# Musca_B1 register map
Vendor: ARM Ltd.; Series: ARMv8-M Mainline; File version: 1.0
CPU: CM33 r0p2, little endian, MPU, FPU, 4 interrupt priority bits, 8 SAU regions
Registers are 32-bit, read-write, reset 0x0 unless marked. A register's access mark holds for its fields unless they carry their own. Offsets are from the block's base; [hi:lo] are bit positions; {n}, {i} and the like mark numbered series; 'fields as' and 'values as' point back to an identical list.

## SystemControl
Base 0x50021000
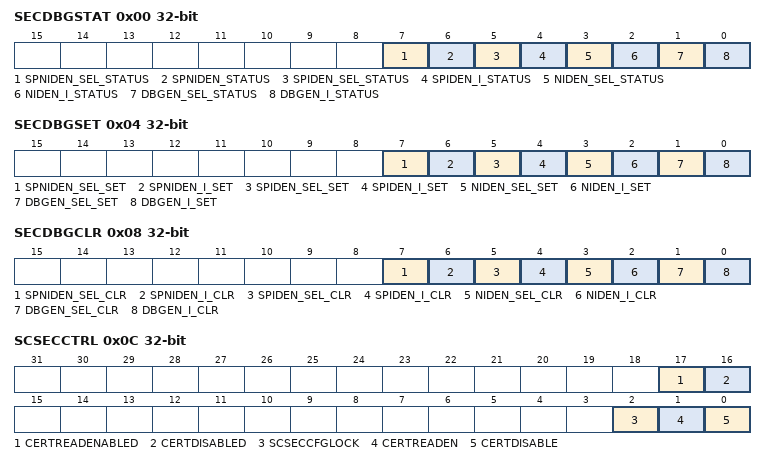
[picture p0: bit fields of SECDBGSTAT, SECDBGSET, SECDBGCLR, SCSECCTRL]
0x00 SECDBGSTAT ro — Secure Debug Configuration Status
  [7] SPNIDEN_SEL_STATUS — Secure privilege non-invasive debug enable selector value
    1=enable (Secure privilege non-invasive debug enable selector); 0=disable (Secure privilege non-invasive debug disable selector)
  [6] SPNIDEN_STATUS — Secure privilege non-invasive debug enable value
    1=enable (Secure privilege non-invasive debug enable); 0=disable (Secure privilege non-invasive debug disable)
  [5] SPIDEN_SEL_STATUS — Secure privilege invasive debug enable selector value
    1=enable (Secure privilege invasive debug enable selector); 0=disable (Secure privilege invasive debug disable selector)
  [4] SPIDEN_I_STATUS — Secure privilege invasive debug enable value
    1=enable (Secure privilege invasive debug enable); 0=disable (Secure privilege invasive debug disable)
  [3] NIDEN_SEL_STATUS — Non-invasive debug enable selector value
    1=enable (non-invasive debug enable selector); 0=disable (non-invasive debug disable selector)
  [2] NIDEN_I_STATUS — Non-invasive debug enable value
    1=enable (non-invasive debug enable); 0=disable (non-invasive debug disable)
  [1] DBGEN_SEL_STATUS — Debug enable selector value
    1=enable (debug enable selector); 0=disable (debug disable selector)
  [0] DBGEN_I_STATUS — Debug enable value
    1=enable (debug enable); 0=disable (debug disable)
0x04 SECDBGSET wo — Secure Debug Configuration Set
  [7] SPNIDEN_SEL_SET — Secure privilege non-invasive debug enable selector set control
    1=enable (Secure privilege non-invasive debug enable selector set control); 0=disable (Secure privilege non-invasive debug disable selector set control)
  [6] SPNIDEN_I_SET — Secure privilege non-invasive debug enable set control
    1=enable (Secure privilege non-invasive debug enable set control); 0=disable (Secure privilege non-invasive debug disable set control)
  [5] SPIDEN_SEL_SET — Secure privilege invasive debug enable selector set control
    1=enable (Secure privilege invasive debug enable selector set control); 0=disable (Secure privilege invasive debug disable selector set control)
  [4] SPIDEN_I_SET — Secure privilege invasive debug enable set control
    1=enable (Secure privilege invasive debug enable set control); 0=disable (Secure privilege invasive debug disable set control)
  [3] NIDEN_SEL_SET — Non-invasive debug enable selector set control
    1=enable (non-invasive debug enable selector set control); 0=disable (non-invasive debug disable selector set control)
  [2] NIDEN_I_SET — Non-invasive debug enable set control
    1=enable (non-invasive debug enable set control); 0=disable (non-invasive debug disable set control)
  [1] DBGEN_SEL_SET — Debug enable selector set control
    1=enable (debug enable selector set control); 0=disable (debug disable selector set control)
  [0] DBGEN_I_SET — High active debug enable set control
0x08 SECDBGCLR wo — Secure Debug Configuration Clear
  [7] SPNIDEN_SEL_CLR — Secure privilege non-invasive debug enable selector clear control
    1=enable (Secure privilege non-invasive debug enable selector clear control); 0=disable (Secure privilege non-invasive debug disable selector clear control)
  [6] SPNIDEN_I_CLR — Secure privilege non-invasive debug enable clear control
    1=enable (Secure privilege non-invasive debug enable clear control); 0=disable (Secure privilege non-invasive debug disable clear control)
  [5] SPIDEN_SEL_CLR — Secure privilege invasive debug enable selector clear control
    1=enable (Secure privilege invasive debug enable selector clear control); 0=disable (Secure privilege invasive debug disable selector clear control)
  [4] SPIDEN_I_CLR — Secure privilege invasive debug enable clear control
    1=enable (Secure privilege invasive debug enable clear control); 0=disable (Secure privilege invasive debug disable clear control)
  [3] NIDEN_SEL_CLR — Non-invasive debug enable selector clear control
    1=enable (non-invasive debug enable selector clear control); 0=disable (non-invasive debug disable selector clear control)
  [2] NIDEN_I_CLR — Non-invasive debug enable clear control
    1=enable (non-invasive debug enable clear control); 0=disable (non-invasive debug disable clear control)
  [1] DBGEN_SEL_CLR — Debug enable selector clear control
    1=enable (debug enable selector clear control); 0=disable (debug disable selector clear control)
  [0] DBGEN_I_CLR — Debug enable clear control
    1=enable (debug enable clear control); 0=disable (debug disable clear control)
0x0C SCSECCTRL — System Security Control
  [17] CERTREADENABLED — Indicates whether the certification read access is enabled
    1=enabled (certification read access is enabled); 0=disabled (certification read access is disabled)
  [16] CERTDISABLED — Indicates that the Certification write path has been disabled
    1=disabled (Certification write path has been disabled); 0=enabled (Certification write path has been enabled)
  [2] SCSECCFGLOCK — Control to disable writes to security-related control registers in this register block
    1=disable (control to disable writes to security-related control registers in this register block); 0=enable (control to enable writes to security-related control registers in this register block)
  [1] CERTREADEN — Control to enable read access on the certification path as long as CERTDISABLE is also LOW
    1=enable (control to enable read access on the certification path as long as CERTDISABLE is also LOW); 0=disable (control to disable read access on the certification path as long as CERTDISABLE is also LOW)
  [0] CERTDISABLE — Control to disable certification path
    1=disable (control to disable certification path); 0=enable (control to enable certification path)
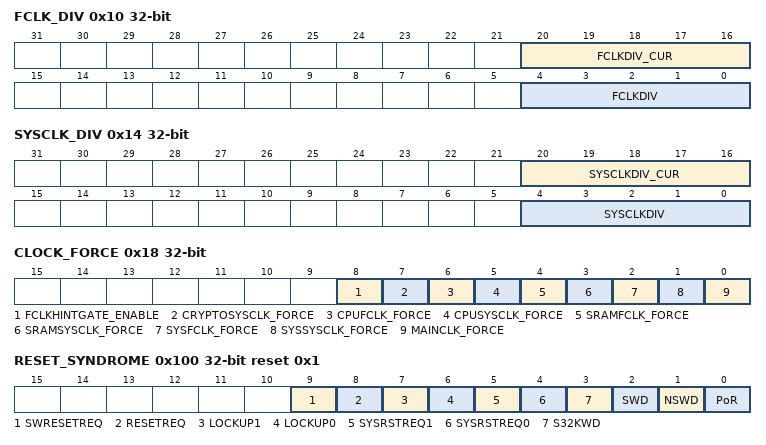
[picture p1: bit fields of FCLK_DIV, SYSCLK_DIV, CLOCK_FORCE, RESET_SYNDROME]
0x10 FCLK_DIV — Fast Clock Divider Configuration
  [20:16] FCLKDIV_CUR ro — Clock Divider Current Value.
  [4:0] FCLKDIV — FCLK from MAINCLK Clock Divider Ratio Request
0x14 SYSCLK_DIV — System Clock Divider Configuration
  [20:16] SYSCLKDIV_CUR ro — Clock Divider Current Value
  [4:0] SYSCLKDIV — SYSCLK from FCLK Clock Divider Ratio Request
0x18 CLOCK_FORCE
  [8] FCLKHINTGATE_ENABLE — Enable FCLK gating by HINTSYSCLKEN when CPU 1 is OFF
    1=Enable FCLK gating by HINTSYSCLKEN when CPU 1 is OFF; 0=latency (improve SRAM3 access latency at the cost of increased power consumption)
  [7] CRYPTOSYSCLK_FORCE — Force all CryptoCell clocks to run when set to HIGH
  [6] CPUFCLK_FORCE — Force all CPU FCLK to run when set to HIGH
  [5] CPUSYSCLK_FORCE — Force all CPU SYSCLK to run when set to HIGH
  [4] SRAMFCLK_FORCE — Force SRAM Local FCLK to run when set to HIGH
  [3] SRAMSYSCLK_FORCE — Force SRAM Local SYSCLK to run when set to HIGH
  [2] SYSFCLK_FORCE — Force Base element Local FCLK to run when set to HIGH
  [1] SYSSYSCLK_FORCE — Force Base element Local SYSCLK to run when set to HIGH
  [0] MAINCLK_FORCE — Force MAINCLK to run when set to HIGH
0x100 RESET_SYNDROME reset 0x1
  [9] SWRESETREQ wo — Software Reset Request
  [8] RESETREQ wo — External Reset Request
  [7] LOCKUP1 wo — CPU 1 Lock-up Status
  [6] LOCKUP0 wo — CPU 0 Lock-up Status
  [5] SYSRSTREQ1 wo — CPU 1 System Reset Request
  [4] SYSRSTREQ0 wo — CPU 0 System Reset Request
  [3] S32KWD wo — Watchdog on the S32KCLK clock
  [2] SWD wo — Secure watchdog
  [1] NSWD wo — Non-secure watchdog
  [0] PoR wo — Power-on
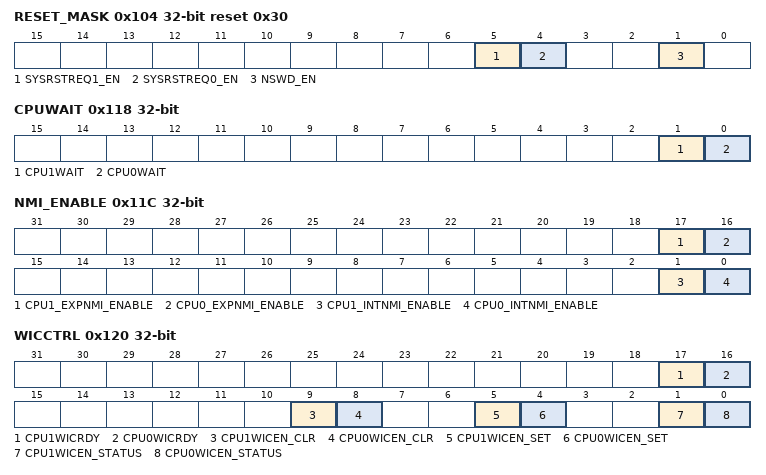
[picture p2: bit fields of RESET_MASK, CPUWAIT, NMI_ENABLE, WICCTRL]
0x104 RESET_MASK reset 0x30
  [5] SYSRSTREQ1_EN — Enable Merging CPU 0 System Reset Request
    1=enabled (Enable Merging CPU 1 System Reset Request); 0=Disabled Merging CPU 1 System Reset Request
  [4] SYSRSTREQ0_EN — Enable Merging CPU 0 System Reset Request
    1=enabled (Enable Merging CPU 0 System Reset Request); 0=Disabled Merging CPU 0 System Reset Request
  [1] NSWD_EN — Enable NON-SECURE WATCHDOG Reset
    1=enabled (Enable NON-SECURE WATCHDOG Reset); 0=Disabled NON-SECURE WATCHDOG Reset
0x108 SWRESET wo — Software Reset
  [9] SWRESETREQ — High Active Software Reset Request
0x10C GRETREG — General Purpose Retention
  [15:0] GRETREG — General Purpose Retention Register
0x110 INITSVRTOR0 — Initial Secure Reset Vector Register For CPU 0
  [31:7] INITSVTOR0 — Default Secure Vector table offset at reset for CPU 0
0x114 INITSVRTOR1 — Initial Secure Reset Vector Register For CPU 1
  [31:7] INITSVTOR1 — Default Secure Vector table offset at reset for CPU 1
0x118 CPUWAIT — CPU Boot wait control after reset
  [1] CPU1WAIT — CPU 1 waits at boot and whether CPU0 powers up
    0=normally or power-up (CPU1 boot normally. From Power ON reset, nSRST reset or Watchdog Reset, CPU 0 powers up); 1=wait or no power-up (CPU1 wait. From Power ON reset, nSRST reset or Watchdog Reset, CPU 0 do not power up)
  [0] CPU0WAIT — CPU 0 waits at boot and whether CPU1 powers up
    0=normally or power-up (CPU0 boot normally. From Power ON reset, nSRST reset or Watchdog Reset, CPU 1 powers up); 1=wait or no power-up (CPU0 wait. From Power ON reset, nSRST reset or Watchdog Reset, CPU 1 do not power up)
0x11C NMI_ENABLE
  [17] CPU1_EXPNMI_ENABLE — CPU1 Externally Sourced NMI Enable
    1=enable (CPU1 Externally Sourced NMI Enabled); 0=disabled (CPU1 Externally Sourced NMI Disabled)
  [16] CPU0_EXPNMI_ENABLE — CPU0 Externally Sourced NMI Enable
    1=enable (CPU0 Externally Sourced NMI Enabled); 0=disabled (CPU0 Externally Sourced NMI Disabled)
  [1] CPU1_INTNMI_ENABLE — CPU1 Internally Sourced NMI Enable
    1=enable (CPU1 Internally Sourced NMI Enabled); 0=disabled (CPU1 Internally Sourced NMI Disabled)
  [0] CPU0_INTNMI_ENABLE — CPU0 Internally Sourced NMI Enable
    1=enable (CPU0 Internally Sourced NMI Enabled); 0=disabled (CPU0 Internally Sourced NMI Disabled)
0x120 WICCTRL — WIC request and acknowledge handshake
  [17] CPU1WICRDY ro — CPU 1 WIC Enable Acknowledge
    1=enabled (CPU 1 WIC Enabled); 0=disabled (CPU 1 WIC Disabled)
  [16] CPU0WICRDY ro — CPU 0 WIC Enable Acknowledge
    1=enabled (CPU 0 WIC Enabled); 0=disabled (CPU 0 WIC Disabled)
  [9] CPU1WICEN_CLR wo — High Active CPU 1 WIC Enable Request Clear
  [8] CPU0WICEN_CLR wo — High Active CPU 0 WIC Enable Request Clear
  [5] CPU1WICEN_SET wo — High Active CPU 1 WIC Enable Request Set
  [4] CPU0WICEN_SET wo — High Active CPU 0 WIC Enable Request Set
  [1] CPU1WICEN_STATUS ro — CPU 1 WIC Enable Request Status
    1=enable (CPU 1 WIC request enabled); 0=disabled (CPU 1 WIC request disabled)
  [0] CPU0WICEN_STATUS ro — CPU 0 WIC Enable Request Status
    1=enable (CPU 0 WIC request enabled); 0=disabled (CPU 0 WIC request disabled)
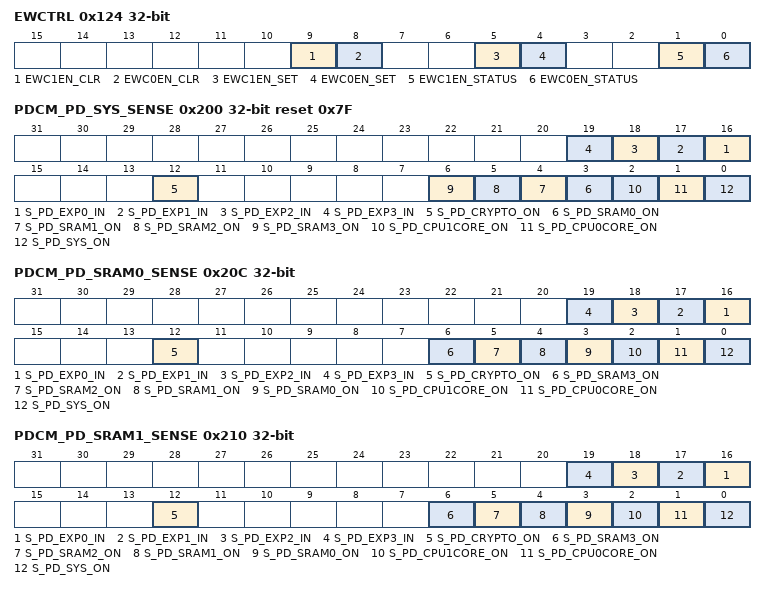
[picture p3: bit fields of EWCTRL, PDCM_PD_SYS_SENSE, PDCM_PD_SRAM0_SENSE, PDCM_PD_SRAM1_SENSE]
0x124 EWCTRL — External Wakeup Control
  [9] EWC1EN_CLR wo — High Active External Wakeup Controller 1 Clear
  [8] EWC0EN_CLR wo — High Active External Wakeup Controller 0 Clear
  [5] EWC1EN_SET wo — High Active External Wakeup Controller 1 Set
  [4] EWC0EN_SET wo — EHigh Active External Wakeup Controller 0 Set
  [1] EWC1EN_STATUS ro — External Wakeup Controller 1 Enable
    1=enable (External Wakeup Controller 1 Enabled); 0=disabled (External Wakeup Controller 1 Disabled)
  [0] EWC0EN_STATUS ro — External Wakeup Controller 0 Enable
    1=enable (External Wakeup Controller 0 Enabled); 0=disabled (External Wakeup Controller 0 Disabled)
0x200 PDCM_PD_SYS_SENSE reset 0x7F — External Wakeup Control
  [n+16] S_PD_EXP{n}_IN (n=0..3) — Enable PDEXPIN[{n}] signal Sensitivity
    1=Enable PDEXPIN[{n}] signal Sensitivity; 0=disabled (Disable PDEXPIN[{n}] signal Sensitivity.)
  [12] S_PD_CRYPTO_ON ro — Tied to HIGH
    1=high (PD_SYS always tries to keep ON if S_PD_CRYPTO_ON is ON)
  [n+3] S_PD_SRAM{n}_ON ro (n=0..3) — Tied to HIGH
    1=high (PD_SYS always tries to keep ON if SRAM{n} power domain is ON)
  [2] S_PD_CPU1CORE_ON ro — Tied to HIGH
    1=high (PD_SYS always tries to stay ON if PD_CPU1CORE is ON)
  [1] S_PD_CPU0CORE_ON ro — Tied to HIGH
    1=high (PD_SYS always tries to stay ON if PD_CPU0CORE is ON)
  [0] S_PD_SYS_ON — Enable PD_SYS ON Sensitivity
    1=enable (Keep PD_SYS awake after powered ON)
0x20C PDCM_PD_SRAM0_SENSE — Power Control Depedendency Matrix PD_SRAM0 Power Domain Sensitivity
  [n+16] S_PD_EXP{n}_IN (n=0..3) — Enable PDEXPIN[{n}] signal Sensitivity
    1=Enable PDEXPIN[{n}] signal Sensitivity; 0=Disable PDEXPIN[{n}] signal Sensitivity
  [12] S_PD_CRYPTO_ON ro — Tied LOW
    0=Low (Ignores PD_CRYPTO)
  [6] S_PD_SRAM3_ON ro — Tied LOW
    0=Low (Ignores PD_SRAM3 state)
  [5] S_PD_SRAM2_ON ro — Tied LOW
    0=Low (Ignores PD_SRAM2 state)
  [4] S_PD_SRAM1_ON ro — Tied LOW
    0=Low (Ignores PD_SRAM1 state)
  [3] S_PD_SRAM0_ON — Enable sensitivity to PD_SRAM0
    1=Enable sensitivity to PD_SRAM0; 0=Disable sensitivity to PD_SRAM0
  [2] S_PD_CPU1CORE_ON — Enable sensitivity to PD_CPU1CORE
    1=Enable sensitivity to PD_CPU1CORE; 0=Disable sensitivity to PD_CPU1CORE
  [1] S_PD_CPU0CORE_ON — Enable sensitivity to PD_CPU0CORE
    1=Enable sensitivity to PD_CPU0CORE; 0=Disable sensitivity to PD_CPU0CORE
  [0] S_PD_SYS_ON — Enable sensitivity to PD_SYS
    1=Enable sensitivity to PD_SYS; 0=Disable sensitivity to PD_SYS
0x210 PDCM_PD_SRAM1_SENSE — Power Control Depedendency Matrix PD_SRAM1 Power Domain Sensitivity
  [n+16] S_PD_EXP{n}_IN (n=0..3) — Enable PDEXPIN[{n}] signal Sensitivity
    values as PDCM_PD_SRAM0_SENSE.S_PD_EXP0_IN
  [12] S_PD_CRYPTO_ON ro — Tied LOW
    0=Low (Ignores PD_CRYPTO)
  [6] S_PD_SRAM3_ON ro — Tied LOW
    0=Low (Ignores PD_SRAM3 state)
  [5] S_PD_SRAM2_ON ro — Tied LOW
    0=Low (Ignores PD_SRAM2 state)
  [4] S_PD_SRAM1_ON — Enable sensitivity to PD_SRAM1
    1=Enable sensitivity to PD_SRAM1; 0=Disable sensitivity to PD_SRAM1
  [3] S_PD_SRAM0_ON ro — Tied LOW
    0=Low (Ignores PD_SRAM0 state)
  [2] S_PD_CPU1CORE_ON — Enable sensitivity to PD_CPU1CORE
    values as PDCM_PD_SRAM0_SENSE.S_PD_CPU1CORE_ON
  [1] S_PD_CPU0CORE_ON — Enable sensitivity to PD_CPU0CORE
    values as PDCM_PD_SRAM0_SENSE.S_PD_CPU0CORE_ON
  [0] S_PD_SYS_ON — Enable sensitivity to PD_SYS
    values as PDCM_PD_SRAM0_SENSE.S_PD_SYS_ON
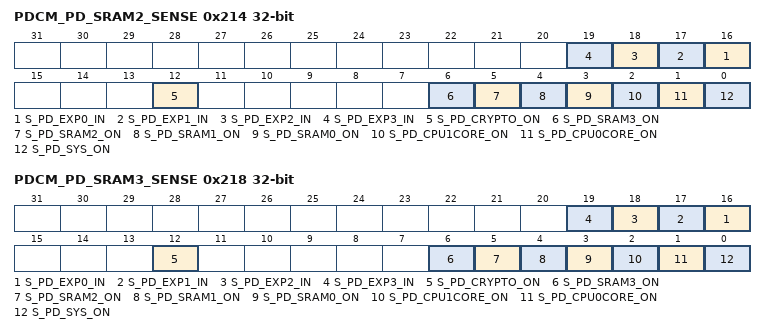
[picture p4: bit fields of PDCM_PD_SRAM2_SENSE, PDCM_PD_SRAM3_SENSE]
0x214 PDCM_PD_SRAM2_SENSE — Power Control Depedendency Matrix PD_SRAM2 Power Domain Sensitivity
  [n+16] S_PD_EXP{n}_IN (n=0..3) — Enable PDEXPIN[{n}] signal Sensitivity
    values as PDCM_PD_SRAM0_SENSE.S_PD_EXP0_IN
  [12] S_PD_CRYPTO_ON ro — Tied LOW
    0=Low (Ignores PD_CRYPTO)
  [6] S_PD_SRAM3_ON ro — Tied LOW
    0=Low (Ignores PD_SRAM3 state)
  [5] S_PD_SRAM2_ON — Enable sensitivity to PD_SRAM2
    1=Enable sensitivity to PD_SRAM2; 0=Disable sensitivity to PD_SRAM2
  [4] S_PD_SRAM1_ON ro — Tied LOW
    0=Low (Ignores PD_SRAM1 state)
  [3] S_PD_SRAM0_ON ro — Tied LOW
    0=Low (Ignores PD_SRAM0 state)
  [2] S_PD_CPU1CORE_ON — Enable sensitivity to PD_CPU1CORE
    values as PDCM_PD_SRAM0_SENSE.S_PD_CPU1CORE_ON
  [1] S_PD_CPU0CORE_ON — Enable sensitivity to PD_CPU0CORE
    values as PDCM_PD_SRAM0_SENSE.S_PD_CPU0CORE_ON
  [0] S_PD_SYS_ON — Enable sensitivity to PD_SYS
    values as PDCM_PD_SRAM0_SENSE.S_PD_SYS_ON
0x218 PDCM_PD_SRAM3_SENSE — Power Control Depedendency Matrix PD_SRAM3 Power Domain Sensitivity
  [n+16] S_PD_EXP{n}_IN (n=0..3) — Enable PDEXPIN[{n}] signal Sensitivity
    values as PDCM_PD_SRAM0_SENSE.S_PD_EXP0_IN
  [12] S_PD_CRYPTO_ON ro — Tied LOW
    0=Low (Ignores PD_CRYPTO)
  [6] S_PD_SRAM3_ON — Enable sensitivity to PD_SRAM3
    1=Enable sensitivity to PD_SRAM3; 0=Disable sensitivity to PD_SRAM3
  [5] S_PD_SRAM2_ON ro — Tied LOW
    0=Low (Ignores PD_SRAM2 state)
  [4] S_PD_SRAM1_ON ro — Tied LOW
    0=Low (Ignores PD_SRAM1 state)
  [3] S_PD_SRAM0_ON ro — Tied LOW
    0=Low (Ignores PD_SRAM0 state)
  [2] S_PD_CPU1CORE_ON — Enable sensitivity to PD_CPU1CORE
    values as PDCM_PD_SRAM0_SENSE.S_PD_CPU1CORE_ON
  [1] S_PD_CPU0CORE_ON — Enable sensitivity to PD_CPU0CORE
    values as PDCM_PD_SRAM0_SENSE.S_PD_CPU0CORE_ON
  [0] S_PD_SYS_ON — Enable sensitivity to PD_SYS
    values as PDCM_PD_SRAM0_SENSE.S_PD_SYS_ON
0xFD0 PIDR4 ro reset 0x4 — Peripheral ID 4
0xFE0 PIDR0 ro reset 0x54 — Peripheral ID 0
0xFE4 PIDR1 ro reset 0xB8 — Peripheral ID 1
0xFE8 PIDR2 ro reset 0x1B — Peripheral ID 2
0xFEC PIDR3 ro — Peripheral ID 3
0xFF0 CIDR0 ro reset 0xD — Component ID 0
0xFF4 CIDR1 ro reset 0xF0 — Component ID 1
0xFF8 CIDR2 ro reset 0x5 — Component ID 2
0xFFC CIDR3 ro reset 0xB1 — Component ID 3
